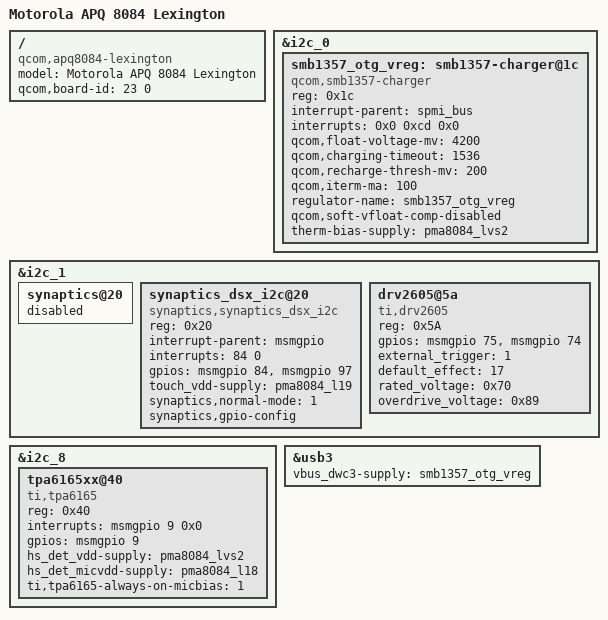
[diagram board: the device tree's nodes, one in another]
/* Copyright (c) 2013, The Linux Foundation. All rights reserved.
 *
 * This program is free software; you can redistribute it and/or modify
 * it under the terms of the GNU General Public License version 2 and
 * only version 2 as published by the Free Software Foundation.
 *
 * This program is distributed in the hope that it will be useful,
 * but WITHOUT ANY WARRANTY; without even the implied warranty of
 * MERCHANTABILITY or FITNESS FOR A PARTICULAR PURPOSE.  See the
 * GNU General Public License for more details.
 */

/dts-v1/;

#include "apq8084.dtsi"
#include "apq8084-lexington.dtsi"

/ {
	model = "Motorola APQ 8084 Lexington";
	compatible = "qcom,apq8084-lexington",
		   "qcom,apq8084-moto",
		   "qcom,apq8084";
	qcom,board-id = <23 0>;
};

&i2c_0 {
	smb1357_otg_vreg: smb1357-charger@1c {
		compatible = "qcom,smb1357-charger";
		reg = <0x1c>;
		interrupt-parent = <&spmi_bus>;
		interrupts = <0x0 0xcd 0x0>;	/* PMA8084 GPIO 14 */
		qcom,float-voltage-mv = <4200>;
		qcom,charging-timeout = <1536>;
		qcom,recharge-thresh-mv = <200>;
		qcom,iterm-ma = <100>;
		regulator-name = "smb1357_otg_vreg";
		qcom,soft-vfloat-comp-disabled;
		therm-bias-supply = <&pma8084_lvs2>;
	};
};

&i2c_1 {
	synaptics@20 {
		status = "disabled";
	};

	synaptics_dsx_i2c@20 {
		compatible = "synaptics,synaptics_dsx_i2c";
		reg = <0x20>;
		interrupt-parent = <&msmgpio>;
		interrupts = <84 0>;
		gpios = <&msmgpio 84 0>, /* IRQ */
			<&msmgpio 97 0>; /* RESET */
		touch_vdd-supply = <&pma8084_l19>;
		synaptics,normal-mode = <1>;
		synaptics,gpio-config;
	};
	/* TI drv2605 */
	drv2605@5a {
		compatible = "ti,drv2605";
		reg = <0x5A>;
		gpios = <&msmgpio 75 0>,        /* EN_GPIO */
			<&msmgpio 74 0>;        /* Trigger */
		external_trigger = <1>;
		default_effect = <17>;          /* Strong Click 100% */
		rated_voltage = <0x70>;         /* 2.4v */
		overdrive_voltage = <0x89>;     /* 3.0v */
	};
};

&i2c_8 {
	tpa6165xx@40 {
		compatible = "ti,tpa6165";
		reg = <0x40>;
		interrupts = <&msmgpio 9 0x0>;
		gpios = <&msmgpio 9 0x0>;
		hs_det_vdd-supply = <&pma8084_lvs2>;
		hs_det_micvdd-supply = <&pma8084_l18>;
		ti,tpa6165-always-on-micbias = <1>;
	};
};

&usb3 {
	vbus_dwc3-supply = <&smb1357_otg_vreg>;
};
